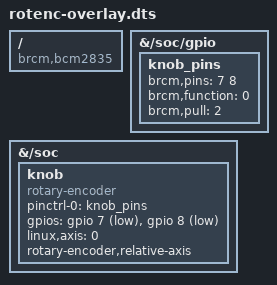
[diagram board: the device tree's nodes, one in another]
/*
 * rotary-overlay.dts
 * Links:
 * https://www.raspberrypi.org/documentation/configuration/device-tree.md
 * https://www.kernel.org/doc/Documentation/input/rotary-encoder.txt
 * https://git.kernel.org/cgit/linux/kernel/git/stable/linux-stable.git/tree/drivers/input/misc/rotary_encoder.c
 */

/dts-v1/;
/plugin/;

/ {
    compatible = "brcm,bcm2835", "brcm,bcm2708", "brcm,bcm2709";

    fragment@0 {
        target-path = "/soc/gpio";
        __overlay__ {
            knob_pins: knob_pins {
                brcm,pins = <7 8>;
                brcm,function = <0>;
                brcm,pull = <2>;
            };
        };
    };

    fragment@1 {
        target-path = "/soc";
        __overlay__ {
            knob: knob {
                compatible = "rotary-encoder";
                #address-cells = <1>;
                #size-cells = <0>;
                pinctrl-names = "default";
                pinctrl-0 = <&knob_pins>;
                gpios = <&gpio 7 1>, <&gpio 8 1>; 
                linux,axis = <0>; /* REL_X */
                rotary-encoder,relative-axis;
            };
        };
    };
    __overrides__ {
        relative_axis =  <&knob>,"rotary-encoder,relative-axis";
        linux_axis =  <&knob>,"linux,axis";
        rollover =  <&knob>,"rotary-encoder,rollover";
        half-period =  <&knob>,"rotary-encoder,half-period";
        steps =  <&knob>,"rotary-encoder,steps";
    };
};																													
